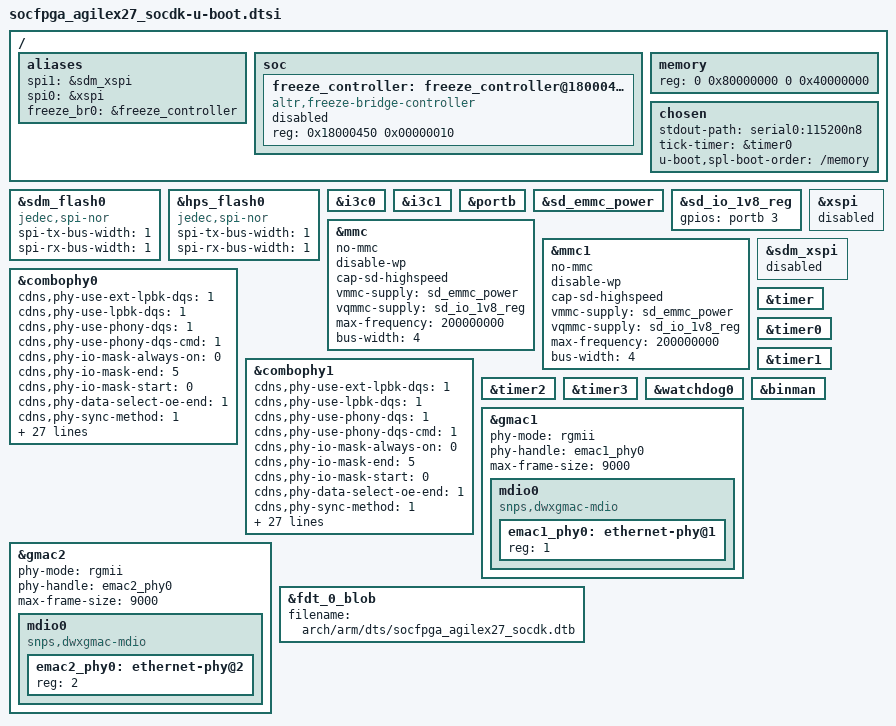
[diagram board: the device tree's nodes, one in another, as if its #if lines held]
// SPDX-License-Identifier: GPL-2.0+
/*
 * U-Boot additions
 *
 * Copyright (C) 2025 Altera Corporation <www.altera.com>
 */

#include "socfpga_agilex27-u-boot.dtsi"

/{
	aliases {
		spi1 = &sdm_xspi;
		spi0 = &xspi;
		freeze_br0 = &freeze_controller;
	};

	soc {
		freeze_controller: freeze_controller@18000450 {
			compatible = "altr,freeze-bridge-controller";
			reg = <0x18000450 0x00000010>;
			status = "disabled";
		};
	};

	memory {
		/* 1GB */
		reg = <0 0x80000000 0 0x40000000>;
	};

	chosen {
		stdout-path = "serial0:115200n8";
		tick-timer = &timer0;
#ifdef CONFIG_TARGET_SOCFPGA_EMU
		u-boot,spl-boot-order = "/memory";
#else
		u-boot,spl-boot-order = &mmc,&mmc1,&hps_flash0,"/memory";
#endif
	};
};

&sdm_flash0 {
	compatible = "jedec,spi-nor";
	spi-tx-bus-width = <1>;
	spi-rx-bus-width = <1>;
	bootph-all;
	/delete-property/ cdns,read-delay;
};

&hps_flash0 {
	compatible = "jedec,spi-nor";
	spi-tx-bus-width = <1>;
	spi-rx-bus-width = <1>;
	bootph-all;
	/delete-property/ cdns,read-delay;
};

&i3c0 {
	bootph-all;
};

&i3c1 {
	bootph-all;
};

&portb {
	bootph-all;
};

&sd_emmc_power {
	bootph-all;
};

&sd_io_1v8_reg {
	gpios = <&portb 3 GPIO_ACTIVE_HIGH>;
	bootph-all;
};

&mmc {
	no-mmc;
	disable-wp;
	cap-sd-highspeed;
	vmmc-supply = <&sd_emmc_power>;
	vqmmc-supply = <&sd_io_1v8_reg>;
	max-frequency = <200000000>;
	bus-width = <4>;
	bootph-all;
};

&mmc1 {
	no-mmc;
	disable-wp;
	cap-sd-highspeed;
	vmmc-supply = <&sd_emmc_power>;
	vqmmc-supply = <&sd_io_1v8_reg>;
	max-frequency = <200000000>;
	bus-width = <4>;
	bootph-all;
};

&combophy0 {
	bootph-all;
	cdns,phy-use-ext-lpbk-dqs = <1>;
	cdns,phy-use-lpbk-dqs = <1>;
	cdns,phy-use-phony-dqs = <1>;
	cdns,phy-use-phony-dqs-cmd = <1>;
	cdns,phy-io-mask-always-on = <0>;
	cdns,phy-io-mask-end = <5>;
	cdns,phy-io-mask-start = <0>;
	cdns,phy-data-select-oe-end = <1>;
	cdns,phy-sync-method = <1>;
	cdns,phy-sw-half-cycle-shift = <0>;
	cdns,phy-rd-del-sel = <52>;
	cdns,phy-underrun-suppress = <1>;
	cdns,phy-gate-cfg-always-on = <1>;
	cdns,phy-param-dll-bypass-mode = <1>;
	cdns,phy-param-phase-detect-sel = <2>;
	cdns,phy-param-dll-start-point = <254>;
	cdns,phy-read-dqs-cmd-delay = <0>;
	cdns,phy-clk-wrdqs-delay = <0>;
	cdns,phy-clk-wr-delay = <0>;
	cdns,phy-read-dqs-delay = <0>;
	cdns,phy-phony-dqs-timing = <0>;
	cdns,hrs09-rddata-en = <1>;
	cdns,hrs09-rdcmd-en = <1>;
	cdns,hrs09-extended-wr-mode = <1>;
	cdns,hrs09-extended-rd-mode = <1>;
	cdns,hrs10-hcsdclkadj = <3>;
	cdns,hrs16-wrdata1-sdclk-dly = <0>;
	cdns,hrs16-wrdata0-sdclk-dly = <0>;
	cdns,hrs16-wrcmd1-sdclk-dly = <0>;
	cdns,hrs16-wrcmd0-sdclk-dly = <0>;
	cdns,hrs16-wrdata1-dly = <0>;
	cdns,hrs16-wrdata0-dly = <0>;
	cdns,hrs16-wrcmd1-dly = <0>;
	cdns,hrs16-wrcmd0-dly = <0>;
	cdns,hrs07-rw-compensate = <10>;
	cdns,hrs07-idelay-val = <0>;
};

&combophy1 {
	bootph-all;
	cdns,phy-use-ext-lpbk-dqs = <1>;
	cdns,phy-use-lpbk-dqs = <1>;
	cdns,phy-use-phony-dqs = <1>;
	cdns,phy-use-phony-dqs-cmd = <1>;
	cdns,phy-io-mask-always-on = <0>;
	cdns,phy-io-mask-end = <5>;
	cdns,phy-io-mask-start = <0>;
	cdns,phy-data-select-oe-end = <1>;
	cdns,phy-sync-method = <1>;
	cdns,phy-sw-half-cycle-shift = <0>;
	cdns,phy-rd-del-sel = <52>;
	cdns,phy-underrun-suppress = <1>;
	cdns,phy-gate-cfg-always-on = <1>;
	cdns,phy-param-dll-bypass-mode = <1>;
	cdns,phy-param-phase-detect-sel = <2>;
	cdns,phy-param-dll-start-point = <254>;
	cdns,phy-read-dqs-cmd-delay = <0>;
	cdns,phy-clk-wrdqs-delay = <0>;
	cdns,phy-clk-wr-delay = <0>;
	cdns,phy-read-dqs-delay = <0>;
	cdns,phy-phony-dqs-timing = <0>;
	cdns,hrs09-rddata-en = <1>;
	cdns,hrs09-rdcmd-en = <1>;
	cdns,hrs09-extended-wr-mode = <1>;
	cdns,hrs09-extended-rd-mode = <1>;
	cdns,hrs10-hcsdclkadj = <3>;
	cdns,hrs16-wrdata1-sdclk-dly = <0>;
	cdns,hrs16-wrdata0-sdclk-dly = <0>;
	cdns,hrs16-wrcmd1-sdclk-dly = <0>;
	cdns,hrs16-wrcmd0-sdclk-dly = <0>;
	cdns,hrs16-wrdata1-dly = <0>;
	cdns,hrs16-wrdata0-dly = <0>;
	cdns,hrs16-wrcmd1-dly = <0>;
	cdns,hrs16-wrcmd0-dly = <0>;
	cdns,hrs07-rw-compensate = <10>;
	cdns,hrs07-idelay-val = <0>;
};

&xspi {
#ifdef CONFIG_TARGET_SOCFPGA_EMU
	status = "disabled";
#else
	status = "okay";
#endif
};

&sdm_xspi {
#ifdef CONFIG_TARGET_SOCFPGA_EMU
	status = "disabled";
#else
	status = "okay";
#endif
};

&timer {
	bootph-all;
};

&timer0 {
	bootph-all;
};

&timer1 {
	bootph-all;
};

&timer2 {
	bootph-all;
};

&timer3 {
	bootph-all;
};

&watchdog0 {
	bootph-all;
};

&gmac1 {
	status = "okay";
	phy-mode = "rgmii";
	phy-handle = <&emac1_phy0>;

	max-frame-size = <9000>;

	mdio0 {
		#address-cells = <1>;
		#size-cells = <0>;
		compatible = "snps,dwxgmac-mdio";
		emac1_phy0: ethernet-phy@1 {
			reg = <1>;
		};
	};
};

&gmac2 {
	status = "okay";
	phy-mode = "rgmii";
	phy-handle = <&emac2_phy0>;

	max-frame-size = <9000>;

	mdio0 {
		#address-cells = <1>;
		#size-cells = <0>;
		compatible = "snps,dwxgmac-mdio";
		emac2_phy0: ethernet-phy@2 {
			reg = <2>;
		};
	};
};

#if !defined(CONFIG_SOCFPGA_SECURE_VAB_AUTH)
&fdt_0_blob {
	filename = "arch/arm/dts/socfpga_agilex27_socdk.dtb";
};

/* To add NAND dtb when ready in future */

&binman {
	/delete-node/ kernel;
};
#endif
